# W806 register map
Vendor: Beijing Lianshengde Micro-electronics Co., Ltd.; File version: 1.0
Registers are 32-bit, read-write, no defined reset value unless marked. A register's access mark holds for its fields unless they carry their own. Offsets are from the block's base; [hi:lo] are bit positions; {n}, {i} and the like mark numbered series.

## RCC — System clock and reset controller
Base 0x40000E00
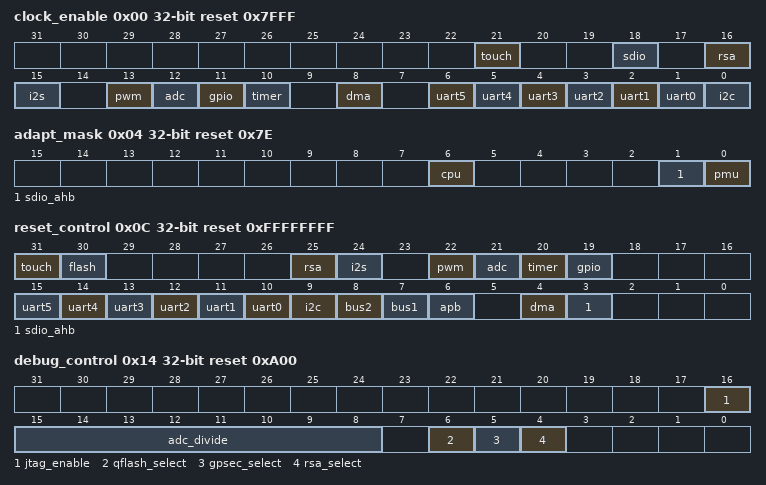
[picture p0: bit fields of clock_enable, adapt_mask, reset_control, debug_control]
0x00 clock_enable reset 0x7FFF (reset mask 0x7FFF) — Software configure clock gate enable . By configuring this clock gating enable register, you can control the clock to shutdown a specified function, so as to achieve the purpose of shutting down a certain module. . In order to provide the firmware with flexibility to control the power consumption of the system, the clock and reset module provides the clock gating function of each module in the system. When the clock of the corresponding module is turned off, the digital logic and clock tree of the module will stop working, which can reduce the dynamic power consumption of the system.
  [all] fields
    0=disable (The clock gate is turned off.); 1=enable (The clock gate is turned on.)
  [21] touch — Touch sensor module clock gate enable . By default, touch sensor module clock gate is enabled.
  [18] sdio — Secure digital input/output clock gate enable . By default, SDIO master module clock gate is enabled.
  [16] rsa — RSA Montgomery coprocessor clock gate enable . By default, RSA clock gate is enabled.
  [15] i2s — Inter-Integrated Sound clock gate enable . By default, I2S clock gate is enabled.
  [13] pwm — Pulse-width modulation module clock gate enable . By default, PWM clock gate is enabled.
  [12] adc — Analog-digital converter clock gate enable
  [11] gpio — General purpose input/output clock gate enable . By default, GPIO clock gate is enabled.
  [10] timer — Timer module clock gate enable . By default, timer clock gate is enabled.
  [8] dma — Direct memory access clock gate enable . By default, DMA clock gate is enabled.
  [n+1] uart{n} (n=0..5) — Universal asynchronous transmitter/receiver enable . By default, UART clock gate is enabled.
  [0] i2c — Inter-Integrated Circuit module enable . By default, I2C clock gate is enabled.
0x04 adapt_mask reset 0x7E — Adaptive clock configuration mask . The chip adaptively turns off the clock of some functional modules according to the transition of some internal states. . Please do not change the configuration, otherwise it may cause system abnormality when configuring PMU function.
  [all] fields
    0=Allow adaptive shutdown and opening; 1=Disallow adaptive shutdown and opening
  [6] cpu — Cpu domain allow adaptive clock configurations . Indicates whether the clock supplied to the CPU clock domain (including CPU, bus1, ROM, SRAM) can be turned off adaptively. . When the CPU needs to enter the WFI state, do not set the adaptive shutdown.
  [1] sdio_ahb — Sdio-Ahb domain allow adaptive clock configurations . Indicates whether the clock supplied to the sdio ahb clock domain can be turned off adaptively.
  [0] pmu — Allow pmu to shutdown gate unit connected to pll output . After the clock output by PLL, there is a gate control unit. This register configuration is used to indicate whether this unit is allowed to be shut down by the PMU.
0x0C reset_control reset 0xFFFFFFFF — Software module reset control . The chip provides the soft reset function of each subsystem, and the subsystem reset can be achieved by setting the corresponding bit of this register to 0. However, the reset state will not be automatically cleared. To restore normal operation, the corresponding bit of this register must be set to 1. . The soft reset function does not reset the CPU and watchdog. In this register, the reset operation of APB, BUS1 and BUS2 (corresponding to APB bus, system bus and data bus) is not recommended, which will cause system access device abnormality.
  [all] fields
    0=Reset the corresponding peripheral; 1=Release the reset state the corresponding peripheral
  [31] touch — Touch sensor module reset
  [30] flash — Flash controller module reset
  [25] rsa — RSA Montgomery coprocessor module reset
  [24] i2s — Inter-Integrated Sound module reset
  [22] pwm — Pulse-width modulation module reset
  [21] adc — Sar-adc module reset
  [20] timer — Timer module reset
  [19] gpio — Gpio module reset
  [n+10] uart{n} (n=0..5) — Universal asynchronous transmitter/receiver reset
  [9] i2c — Inter-Integrated Circuit module reset
  [n+6] bus{n} (n=1..2) — Internal bus reset
  [6] apb — APB bridge module reset
  [4] dma — Direct memory access module reset
  [3] sdio_ahb — Sdio-Ahb clock domain reset
0x10 clock_divide reset 0x3020306 — Software clock division configuration
  [31] frequency — Divide frequency enable . When you need to reconfigure cpu_clk_divider, wlan_clk_divider, bus2_syncdn_factor, sdadc_fdiv, set this register, the hardware will automatically update the above four parameters to the divider, and then clear this register.
    0=in_effect (Frequency division factor has taken effect.); 1=update (Request hardware to update frequency division parameters.)
  [27:24] peripheral — 160-MHz clock divide factor
  [23:16] bus2_sync — Ratio between bus1 and bus2 clock frequency
  [15:8] wlan range 2..255 — PLL to WLAN system divide factor . After dividing the frequency of the clock from the PLL, it is sent to the wlan system. This register is the frequency division factor, the factor should be >= 2.
  [15:8] cpu — PLL to CPU clock divide factor
0x14 debug_control reset 0xA00 — Debug and additional clock control
  [16] jtag_enable — JTAG function enable
    0=Disable JTAG debug function; 1=Enable JTAG debug function
  [15:8] adc_divide — Sigma-Delta Analog-digital Converter frequency division factor . After writing to this field, set bit `update` of register `clock_divide` to take effect.
  [6] qflash_select — QSPI Flash clock source selection
    1=mhz_80 (Use 80 MHz.); 0=mhz_40 (Use 40 MHz.)
  [5] gpsec_select — GPSEC clock source selection
    1=mhz_160 (Use 160 MHz.); 0=mhz_80 (Use 80 MHz.)
  [4] rsa_select — RSA clock source selection
    1=mhz_160 (Use 160 MHz.); 0=mhz_80 (Use 80 MHz.)
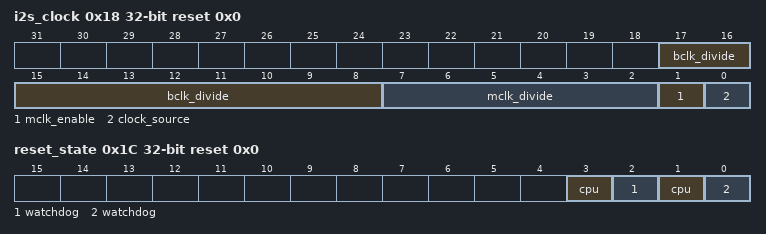
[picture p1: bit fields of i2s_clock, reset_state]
0x18 i2s_clock reset 0x0 — Inter-Integrated Sound clock configuration
  [17:8] bclk_divide — BCLK clock divide factor
  [7:2] mclk_divide — MCLK clock divide factor
  [1] mclk_enable — MCLK clock enable
    0=disable (MCLK is disabled.); 1=enable (MCLK is enabled.)
  [0] clock_source — Use internal I2S clock or external XTAL clock
    0=internal (Use internal clock.); 1=external (Use external XTAL clock. . External clock frequency should be 2 * N * 256 fs, where fs is sample frequency and N must be an integer.)
0x1C reset_state reset 0x0 — CPU and watchdog reset state register
  [3] cpu wo — Write 1 to clear CPU soft reset state.
    1=clear (Write 1 to clear reset state.)
  [2] watchdog wo — Write 1 to clear watchdog soft reset state.
    1=clear (Write 1 to clear reset state.)
  [1] cpu ro — Reads if cpu has been software reset.
    1=has_reset (Reset has procceeded.); 0=No reset have been procceeded
  [0] watchdog ro — Reads if watchdog has been software reset.
    1=has_reset (Reset has procceeded.); 0=No reset have been procceeded
